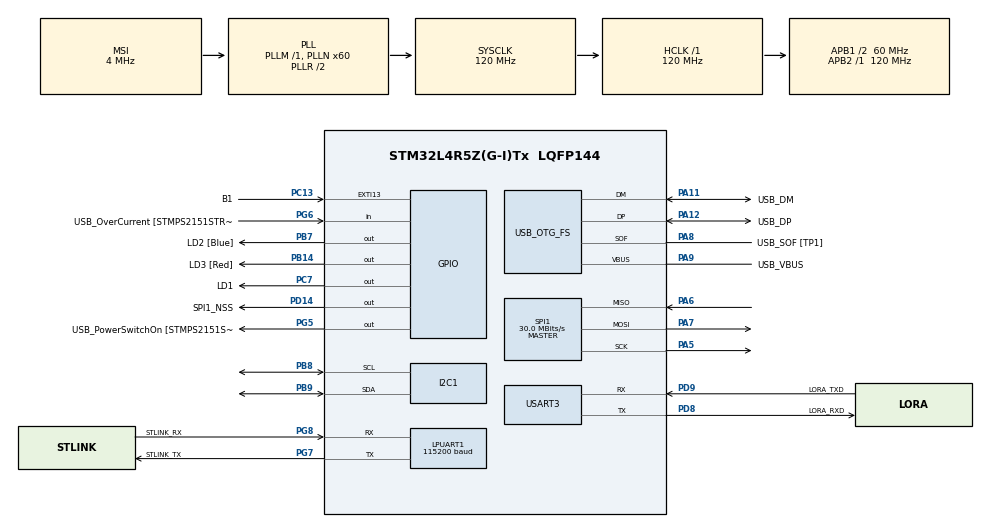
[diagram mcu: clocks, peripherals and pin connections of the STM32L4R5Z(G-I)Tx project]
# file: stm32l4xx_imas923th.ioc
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ADC1.Channel-0\#ChannelRegularConversion=ADC_CHANNEL_TEMPSENSOR
ADC1.ClockPrescaler=ADC_CLOCK_ASYNC_DIV1
ADC1.ContinuousConvMode=DISABLE
ADC1.DMAContinuousRequests=DISABLE
ADC1.DataAlign=ADC_DATAALIGN_RIGHT
ADC1.DiscontinuousConvMode=DISABLE
ADC1.EOCSelection=ADC_EOC_SINGLE_CONV
ADC1.EnableAnalogWatchDog1=false
ADC1.EnableAnalogWatchDog2=false
ADC1.EnableAnalogWatchDog3=false
ADC1.EnableInjectedConversion=DISABLE
ADC1.EnableRegularConversion=ENABLE
ADC1.ExternalTrigConv=ADC_SOFTWARE_START
ADC1.ExternalTrigConvEdge=ADC_EXTERNALTRIGCONVEDGE_NONE
ADC1.LowPowerAutoWait=DISABLE
ADC1.NbrOfConversion=1
ADC1.NbrOfConversionFlag=1
ADC1.OffsetNumber-0\#ChannelRegularConversion=ADC_OFFSET_NONE
ADC1.Overrun=ADC_OVR_DATA_PRESERVED
ADC1.OversamplingMode=DISABLE
ADC1.Rank-0\#ChannelRegularConversion=1
ADC1.Resolution=ADC_RESOLUTION_12B
ADC1.SamplingTime-0\#ChannelRegularConversion=ADC_SAMPLETIME_2CYCLES_5
ADC1.ScanConvMode=ADC_SCAN_DISABLE
ADC1.master=1
I2C1.Timing=0x107075B0
LPUART1.BaudRate=115200
LPUART1.WordLength=UART_WORDLENGTH_8B
Mcu.Family=STM32L4
Mcu.Name=STM32L4R5Z(G-I)Tx
Mcu.Package=LQFP144
NVIC.ADC1_IRQn=true\:0\:0\:false\:false\:true\:true
NVIC.EXTI15_10_IRQn=true\:0\:0\:false\:false\:true\:true
NVIC.I2C1_ER_IRQn=true\:0\:0\:false\:false\:true\:true
NVIC.I2C1_EV_IRQn=true\:0\:0\:false\:false\:true\:true
NVIC.LPUART1_IRQn=true\:0\:0\:false\:false\:true\:true
NVIC.OTG_FS_IRQn=true\:0\:0\:false\:false\:true\:false
NVIC.PriorityGroup=NVIC_PRIORITYGROUP_4
NVIC.SPI1_IRQn=true\:0\:0\:false\:false\:true\:true
NVIC.USART3_IRQn=true\:0\:0\:false\:false\:true\:true
PA10.GPIO_Label=USB_ID
PA10.Signal=USB_OTG_FS_ID
PA11.GPIO_Label=USB_DM
PA11.Mode=Device_Only
PA11.Signal=USB_OTG_FS_DM
PA12.GPIO_Label=USB_DP
PA12.Mode=Device_Only
PA12.Signal=USB_OTG_FS_DP
PA13\ (JTMS/SWDIO).GPIO_Label=TMS
PA13\ (JTMS/SWDIO).Mode=Trace_Asynchronous_SW
PA13\ (JTMS/SWDIO).Signal=SYS_JTMS-SWDIO
PA14\ (JTCK/SWCLK).GPIO_Label=TCK
PA14\ (JTCK/SWCLK).Mode=Trace_Asynchronous_SW
PA14\ (JTCK/SWCLK).Signal=SYS_JTCK-SWCLK
PA5.Mode=Full_Duplex_Master
PA5.Signal=SPI1_SCK
PA6.Mode=Full_Duplex_Master
PA6.Signal=SPI1_MISO
PA7.Mode=Full_Duplex_Master
PA7.Signal=SPI1_MOSI
PA8.GPIO_Label=USB_SOF [TP1]
PA8.Mode=Activate_SOF_FS
PA8.Signal=USB_OTG_FS_SOF
PA9.GPIO_Label=USB_VBUS
PA9.Mode=Activate_VBUS
PA9.Signal=USB_OTG_FS_VBUS
PB14.GPIO_Label=LD3 [Red]
PB14.Signal=GPIO_Output
PB3\ (JTDO/TRACESWO).GPIO_Label=SWO
PB3\ (JTDO/TRACESWO).Mode=Trace_Asynchronous_SW
PB3\ (JTDO/TRACESWO).Signal=SYS_JTDO-SWO
PB7.GPIO_Label=LD2 [Blue]
PB7.Signal=GPIO_Output
PB8.Mode=I2C
PB8.Signal=I2C1_SCL
PB9.Mode=I2C
PB9.Signal=I2C1_SDA
PC13.GPIO_Label=B1
PC13.Signal=GPXTI13
PC14-OSC32_IN\ (PC14).Mode=LSE-External-Oscillator
PC14-OSC32_IN\ (PC14).Signal=RCC_OSC32_IN
PC15-OSC32_OUT\ (PC15).Mode=LSE-External-Oscillator
PC15-OSC32_OUT\ (PC15).Signal=RCC_OSC32_OUT
PC7.GPIO_Label=LD1
PC7.Signal=GPIO_Output
PD14.GPIO_Label=SPI1_NSS
PD14.Signal=GPIO_Output
PD8.GPIO_Label=LORA_RXD
PD8.Mode=Asynchronous
PD8.Signal=USART3_TX
PD9.GPIO_Label=LORA_TXD
PD9.Mode=Asynchronous
PD9.Signal=USART3_RX
PG5.GPIO_Label=USB_PowerSwitchOn [STMPS2151STR_EN]
PG5.Signal=GPIO_Output
PG6.GPIO_Label=USB_OverCurrent [STMPS2151STR_FAULT]
PG6.Signal=GPIO_Input
PG7.GPIO_Label=STLINK_TX
PG7.Mode=Multiprocessor_communication
PG7.Signal=LPUART1_TX
PG8.GPIO_Label=STLINK_RX
PG8.Mode=Multiprocessor_communication
PG8.Signal=LPUART1_RX
PH0-OSC_IN\ (PH0).Mode=HSE-External-Clock-Source
PH0-OSC_IN\ (PH0).Signal=RCC_OSC_IN
PH1-OSC_OUT\ (PH1).Signal=RCC_OSC_OUT
ProjectManager.HeapSize=0x200
ProjectManager.StackSize=0x400
ProjectManager.TargetToolchain=TrueSTUDIO
RCC.48MHZClocksFreq_Value=24000000
RCC.ADCFreq_Value=48000000
RCC.AHBFreq_Value=120000000
RCC.APB1CLKDivider=RCC_HCLK_DIV2
RCC.APB1Freq_Value=60000000
RCC.APB1TimFreq_Value=120000000
RCC.APB2Freq_Value=120000000
RCC.APB2TimFreq_Value=120000000
RCC.CortexFreq_Value=120000000
RCC.HCLKFreq_Value=120000000
RCC.HSE_VALUE=8000000
RCC.HSI48_VALUE=48000000
RCC.HSI_VALUE=16000000
RCC.MSI_VALUE=4000000
RCC.PLLMUL=RCC_PLL_MUL9
RCC.PLLN=60
RCC.PLLSAI1N=24
RCC.PRESCALERUSB=RCC_USBCLKSOURCE_PLL_DIV1_5
RCC.SYSCLKFreq_VALUE=120000000
RCC.SYSCLKSource=RCC_SYSCLKSOURCE_PLLCLK
RCC.SYSCLKSourceVirtual=RCC_SYSCLKSOURCE_PLLCLK
RCC.USBFreq_Value=48000000
RCC.VCOOutputFreq_Value=240000000
SPI1.BaudRatePrescaler=SPI_BAUDRATEPRESCALER_4
SPI1.CalculateBaudRate=30.0 MBits/s
SPI1.DataSize=SPI_DATASIZE_8BIT
SPI1.Direction=SPI_DIRECTION_2LINES
SPI1.Mode=SPI_MODE_MASTER
SPI1.VirtualType=VM_MASTER
USART3.VirtualMode-Asynchronous=VM_ASYNC
USART3.WordLength=WORDLENGTH_8B
USB_DEVICE.CLASS_NAME_FS=DFU
USB_DEVICE.VirtualMode=Dfu
USB_DEVICE.VirtualModeFS=Dfu_FS
USB_OTG_FS.VirtualMode=Device_Only
VP_ADC1_TempSens_Input.Mode=IN-TempSens
VP_ADC1_Vbat_Input.Mode=IN-Vbat
VP_ADC1_Vref_Input.Mode=IN-Vrefint
VP_SYS_V_PVD_IN.Mode=Mode_PVD_Int
VP_USB_DEVICE_VS_USB_DEVICE_DFU_FS.Mode=DFU_FS
board=NUCLEO-L4R5ZI

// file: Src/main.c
/**
  ******************************************************************************
  * @file           : main.c
  * @brief          : Main program body
  ******************************************************************************
  * This notice applies to any and all portions of this file
  * that are not between comment pairs USER CODE BEGIN and
  * USER CODE END. Other portions of this file, whether
  * inserted by the user or by software development tools
  * are owned by their respective copyright owners.
  *
  * Copyright (c) 2018 STMicroelectronics International N.V.
  * All rights reserved.
  *
  * Redistribution and use in source and binary forms, with or without
  * modification, are permitted, provided that the following conditions are met:
  *
  * 1. Redistribution of source code must retain the above copyright notice,
  *    this list of conditions and the following disclaimer.
  * 2. Redistributions in binary form must reproduce the above copyright notice,
  *    this list of conditions and the following disclaimer in the documentation
  *    and/or other materials provided with the distribution.
  * 3. Neither the name of STMicroelectronics nor the names of other
  *    contributors to this software may be used to endorse or promote products
  *    derived from this software without specific written permission.
  * 4. This software, including modifications and/or derivative works of this
  *    software, must execute solely and exclusively on microcontroller or
  *    microprocessor devices manufactured by or for STMicroelectronics.
  * 5. Redistribution and use of this software other than as permitted under
  *    this license is void and will automatically terminate your rights under
  *    this license.
  *
  * THIS SOFTWARE IS PROVIDED BY STMICROELECTRONICS AND CONTRIBUTORS "AS IS"
  * AND ANY EXPRESS, IMPLIED OR STATUTORY WARRANTIES, INCLUDING, BUT NOT
  * LIMITED TO, THE IMPLIED WARRANTIES OF MERCHANTABILITY, FITNESS FOR A
  * PARTICULAR PURPOSE AND NON-INFRINGEMENT OF THIRD PARTY INTELLECTUAL PROPERTY
  * RIGHTS ARE DISCLAIMED TO THE FULLEST EXTENT PERMITTED BY LAW. IN NO EVENT
  * SHALL STMICROELECTRONICS OR CONTRIBUTORS BE LIABLE FOR ANY DIRECT, INDIRECT,
  * INCIDENTAL, SPECIAL, EXEMPLARY, OR CONSEQUENTIAL DAMAGES (INCLUDING, BUT NOT
  * LIMITED TO, PROCUREMENT OF SUBSTITUTE GOODS OR SERVICES; LOSS OF USE, DATA,
  * OR PROFITS; OR BUSINESS INTERRUPTION) HOWEVER CAUSED AND ON ANY THEORY OF
  * LIABILITY, WHETHER IN CONTRACT, STRICT LIABILITY, OR TORT (INCLUDING
  * NEGLIGENCE OR OTHERWISE) ARISING IN ANY WAY OUT OF THE USE OF THIS SOFTWARE,
  * EVEN IF ADVISED OF THE POSSIBILITY OF SUCH DAMAGE.
  *
  ******************************************************************************
  */
#include "main.h"
#include "stm32l4xx_hal.h"
#include "adc.h"
#include "i2c.h"
#include "usart.h"
#include "spi.h"
#include "usb_device.h"
#include "gpio.h"

/* USER CODE BEGIN Includes */
#include <WiMOD_LoRaWAN_API.h>
#include <SerialDevice.h>
/* USER CODE END Includes */

/* USER CODE BEGIN PV */
/* Private variables ---------------------------------------------------------*/

/* USER CODE END PV */

void SystemClock_Config(void);

/* USER CODE BEGIN PFP */
/* Private function prototypes -----------------------------------------------*/

/* USER CODE END PFP */

int main(void)
{

  /* MCU Configuration----------------------------------------------------------*/

  /* Reset of all peripherals, Initializes the Flash interface and the Systick. */
  HAL_Init();

  /* Configure the system clock */
  SystemClock_Config();

  /* Initialize all configured peripherals */
  MX_GPIO_Init();
  MX_LPUART1_UART_Init();
  MX_USART3_UART_Init();
  MX_USB_DEVICE_Init();
  MX_I2C1_Init();
  MX_ADC1_Init();
  MX_SPI1_Init();
  /* USER CODE BEGIN 2 */

  if(!WiMOD_LoRaWAN_Init(&huart3))
  {
//	  printf("error - couldn't open interface on comport:%s\r\n");
//	  printf("try: WiMOD_LoRaWAN_HCI_C_ExampleCode COMxy to select another comport\n\r");

	  _Error_Handler(__FILE__, __LINE__);
  }

  //Send message to UART port
  USART_TxWelcomeMessage();
  USART_ShowMenu();

  /* USER CODE END 2 */

  /* Infinite loop */
  /* USER CODE BEGIN WHILE */
  while (1)
  {
	  // handle receiver process
	  WiMOD_LoRaWAN_Process();
  /* USER CODE END WHILE */

  /* USER CODE BEGIN 3 */
	  USART_CheckAppCmd();

  }
  /* USER CODE END 3 */

}

void SystemClock_Config(void)
{

  RCC_OscInitTypeDef RCC_OscInitStruct;
  RCC_ClkInitTypeDef RCC_ClkInitStruct;
  RCC_PeriphCLKInitTypeDef PeriphClkInit;

    /**Configure the main internal regulator output voltage
    */
  if (HAL_PWREx_ControlVoltageScaling(PWR_REGULATOR_VOLTAGE_SCALE1_BOOST) != HAL_OK)
  {
    _Error_Handler(__FILE__, __LINE__);
  }

    /**Configure LSE Drive Capability
    */
  HAL_PWR_EnableBkUpAccess();

  __HAL_RCC_LSEDRIVE_CONFIG(RCC_LSEDRIVE_LOW);

    /**Initializes the CPU, AHB and APB busses clocks
    */
  RCC_OscInitStruct.OscillatorType = RCC_OSCILLATORTYPE_LSE|RCC_OSCILLATORTYPE_MSI;
  RCC_OscInitStruct.LSEState = RCC_LSE_ON;
  RCC_OscInitStruct.MSIState = RCC_MSI_ON;
  RCC_OscInitStruct.MSICalibrationValue = 0;
  RCC_OscInitStruct.MSIClockRange = RCC_MSIRANGE_6;
  RCC_OscInitStruct.PLL.PLLState = RCC_PLL_ON;
  RCC_OscInitStruct.PLL.PLLSource = RCC_PLLSOURCE_MSI;
  RCC_OscInitStruct.PLL.PLLM = 1;
  RCC_OscInitStruct.PLL.PLLN = 60;
  RCC_OscInitStruct.PLL.PLLP = RCC_PLLP_DIV2;
  RCC_OscInitStruct.PLL.PLLQ = RCC_PLLQ_DIV2;
  RCC_OscInitStruct.PLL.PLLR = RCC_PLLR_DIV2;
  if (HAL_RCC_OscConfig(&RCC_OscInitStruct) != HAL_OK)
  {
    _Error_Handler(__FILE__, __LINE__);
  }

    /**Initializes the CPU, AHB and APB busses clocks
    */
  RCC_ClkInitStruct.ClockType = RCC_CLOCKTYPE_HCLK|RCC_CLOCKTYPE_SYSCLK
                              |RCC_CLOCKTYPE_PCLK1|RCC_CLOCKTYPE_PCLK2;
  RCC_ClkInitStruct.SYSCLKSource = RCC_SYSCLKSOURCE_PLLCLK;
  RCC_ClkInitStruct.AHBCLKDivider = RCC_SYSCLK_DIV1;
  RCC_ClkInitStruct.APB1CLKDivider = RCC_HCLK_DIV2;
  RCC_ClkInitStruct.APB2CLKDivider = RCC_HCLK_DIV1;

  if (HAL_RCC_ClockConfig(&RCC_ClkInitStruct, FLASH_LATENCY_5) != HAL_OK)
  {
    _Error_Handler(__FILE__, __LINE__);
  }

  PeriphClkInit.PeriphClockSelection = RCC_PERIPHCLK_USART3|RCC_PERIPHCLK_LPUART1
                              |RCC_PERIPHCLK_I2C1|RCC_PERIPHCLK_USB
                              |RCC_PERIPHCLK_ADC;
  PeriphClkInit.Usart3ClockSelection = RCC_USART3CLKSOURCE_PCLK1;
  PeriphClkInit.Lpuart1ClockSelection = RCC_LPUART1CLKSOURCE_PCLK1;
  PeriphClkInit.I2c1ClockSelection = RCC_I2C1CLKSOURCE_PCLK1;
  PeriphClkInit.AdcClockSelection = RCC_ADCCLKSOURCE_PLLSAI1;
  PeriphClkInit.UsbClockSelection = RCC_USBCLKSOURCE_PLLSAI1;
  PeriphClkInit.PLLSAI1.PLLSAI1Source = RCC_PLLSOURCE_MSI;
  PeriphClkInit.PLLSAI1.PLLSAI1M = 1;
  PeriphClkInit.PLLSAI1.PLLSAI1N = 24;
  PeriphClkInit.PLLSAI1.PLLSAI1P = RCC_PLLP_DIV2;
  PeriphClkInit.PLLSAI1.PLLSAI1Q = RCC_PLLQ_DIV2;
  PeriphClkInit.PLLSAI1.PLLSAI1R = RCC_PLLR_DIV2;
  PeriphClkInit.PLLSAI1.PLLSAI1ClockOut = RCC_PLLSAI1_48M2CLK|RCC_PLLSAI1_ADC1CLK;
  if (HAL_RCCEx_PeriphCLKConfig(&PeriphClkInit) != HAL_OK)
  {
    _Error_Handler(__FILE__, __LINE__);
  }

    /**Configure the Systick interrupt time
    */
  HAL_SYSTICK_Config(HAL_RCC_GetHCLKFreq()/1000);

    /**Configure the Systick
    */
  HAL_SYSTICK_CLKSourceConfig(SYSTICK_CLKSOURCE_HCLK);

    /**Enable MSI Auto calibration
    */
  HAL_RCCEx_EnableMSIPLLMode();

  /* SysTick_IRQn interrupt configuration */
  HAL_NVIC_SetPriority(SysTick_IRQn, 0, 0);
}

/* USER CODE BEGIN 4 */
int _write(int file, char *ptr, int len)
{
	HAL_UART_Transmit(&hlpuart1,(uint8_t *)ptr,len,HAL_MAX_DELAY);
	return len;
}

/* USER CODE END 4 */

void _Error_Handler(char *file, int line)
{
  while(1)
  {
  }
}

/************************ (C) COPYRIGHT STMicroelectronics *****END OF FILE****/
